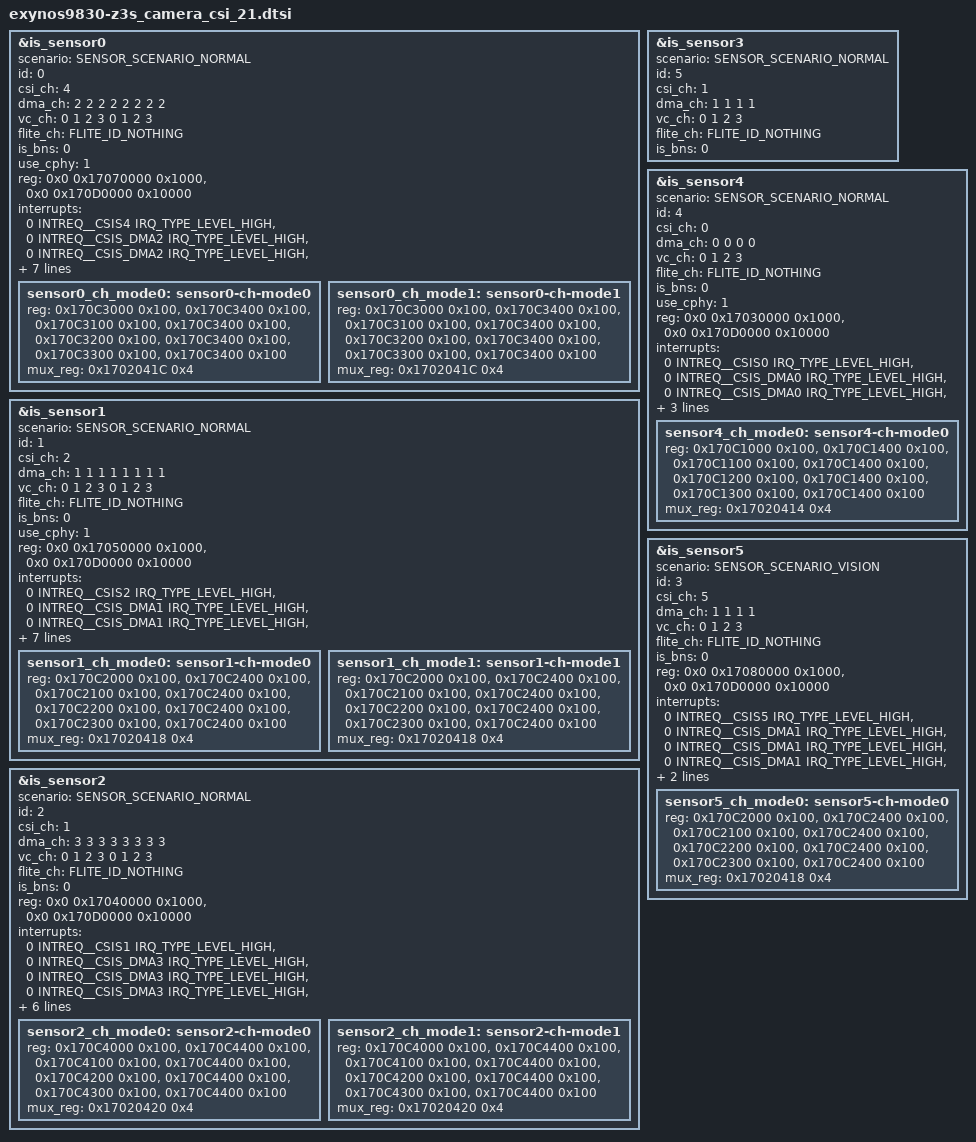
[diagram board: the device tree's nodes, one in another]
/*
 * Samsung Exynos SoC series Pablo driver
 *
 * Copyright (c) 2019 Samsung Electronics Co., Ltd
 *
 * This program is free software; you can redistribute it and/or modify
 * it under the terms of the GNU General Public License version 2 as
 * published by the Free Software Foundation.
 */

#include <dt-bindings/camera/exynos_is_dt.h>
#include <dt-bindings/interrupt-controller/exynos9830.h>
#include <dt-bindings/clock/exynos9830.h>

/* REAR CAMERA */
&is_sensor0 {
	#address-cells = <1>;
	#size-cells = <1>;
	scenario = <SENSOR_SCENARIO_NORMAL>;	/* Normal, Vision, OIS etc */
	id = <0>;
	csi_ch = <4>;
	dma_ch = <2 2 2 2
		2 2 2 2>;
	vc_ch = <0 1 2 3
		0 1 2 3>;
	flite_ch = <FLITE_ID_NOTHING>;
	is_bns = <0>;
	status = "okay";
	use_cphy = <1>;

	reg = <0x0 0x17070000 0x1000>, /* MIPI-CSI4 */
		<0x0 0x170D0000 0x10000>; /* PHY: M0S4S4S4S4S4S2 */
	reg-names = "csi", "phy";

	interrupts = <0 INTREQ__CSIS4 IRQ_TYPE_LEVEL_HIGH>, /* MIPI-CSI4 */
		<0 INTREQ__CSIS_DMA2 IRQ_TYPE_LEVEL_HIGH>,
		<0 INTREQ__CSIS_DMA2 IRQ_TYPE_LEVEL_HIGH>,
		<0 INTREQ__CSIS_DMA2 IRQ_TYPE_LEVEL_HIGH>,
		<0 INTREQ__CSIS_DMA2 IRQ_TYPE_LEVEL_HIGH>,
		<0 INTREQ__CSIS_DMA2 IRQ_TYPE_LEVEL_HIGH>,
		<0 INTREQ__CSIS_DMA2 IRQ_TYPE_LEVEL_HIGH>,
		<0 INTREQ__CSIS_DMA2 IRQ_TYPE_LEVEL_HIGH>,
		<0 INTREQ__CSIS_DMA2 IRQ_TYPE_LEVEL_HIGH>;
	interrupt-names = "csi",
		"mode0_VC0", "mode0_VC1","mode0_VC2","mode0_VC3",
		"mode1_VC0", "mode1_VC1","mode1_VC2","mode1_VC3";

	phys = <&mipi_phy_csis4_m0s4s4s4s4s4s2 0>;
	phy-names = "csis_dphy";

	/* without PAF HW */
	sensor0_ch_mode0: sensor0-ch-mode0 {
		reg = <0x170C3000 0x100>, /* DMA2 VC0 */
			<0x170C3400 0x100>, /* DMA2 Common */
			<0x170C3100 0x100>, /* DMA2 VC1 */
			<0x170C3400 0x100>, /* DMA2 Common */
			<0x170C3200 0x100>, /* DMA2 VC2 */
			<0x170C3400 0x100>, /* DMA2 Common */
			<0x170C3300 0x100>, /* DMA2 VC3 */
			<0x170C3400 0x100>; /* DMA2 Common */
		mux_reg = <0x1702041C 0x4>; /* DMA2 input mux */
	};

	/* with PAF HW */
	sensor0_ch_mode1: sensor0-ch-mode1 {
		reg = <0x170C3000 0x100>, /* DMA2 VC0 */
			<0x170C3400 0x100>, /* DMA2 Common */
			<0x170C3100 0x100>, /* DMA2 VC1 */
			<0x170C3400 0x100>, /* DMA2 Common */
			<0x170C3200 0x100>, /* DMA2 VC2 */
			<0x170C3400 0x100>, /* DMA2 Common */
			<0x170C3300 0x100>, /* DMA2 VC3 */
			<0x170C3400 0x100>; /* DMA2 Common */
		mux_reg = <0x1702041C 0x4>; /* DMA2 input mux */
	};
};

/* FRONT CAMERA */
&is_sensor1 {
	#address-cells = <1>;
	#size-cells = <1>;
	scenario = <SENSOR_SCENARIO_NORMAL>;    /* Normal, Vision, OIS etc */
	id = <1>;
	csi_ch = <2>;
	dma_ch = <1 1 1 1
		1 1 1 1>;
	vc_ch = <0 1 2 3
		0 1 2 3>;
	flite_ch = <FLITE_ID_NOTHING>;
	is_bns = <0>;
	status = "okay";
	use_cphy = <1>;

	reg = <0x0 0x17050000 0x1000>, /* MIPI-CSI2 */
	      <0x0 0x170D0000 0x10000>; /* PHY: M0S4S4S4S4S4S2 */
	reg-names = "csi", "phy";

	interrupts = <0 INTREQ__CSIS2 IRQ_TYPE_LEVEL_HIGH>, /* MIPI-CSI2 */
		<0 INTREQ__CSIS_DMA1 IRQ_TYPE_LEVEL_HIGH>,
		<0 INTREQ__CSIS_DMA1 IRQ_TYPE_LEVEL_HIGH>,
		<0 INTREQ__CSIS_DMA1 IRQ_TYPE_LEVEL_HIGH>,
		<0 INTREQ__CSIS_DMA1 IRQ_TYPE_LEVEL_HIGH>,
		<0 INTREQ__CSIS_DMA1 IRQ_TYPE_LEVEL_HIGH>,
		<0 INTREQ__CSIS_DMA1 IRQ_TYPE_LEVEL_HIGH>,
		<0 INTREQ__CSIS_DMA1 IRQ_TYPE_LEVEL_HIGH>,
		<0 INTREQ__CSIS_DMA1 IRQ_TYPE_LEVEL_HIGH>;
	interrupt-names = "csi",
		"mode0_VC0", "mode0_VC1","mode0_VC2","mode0_VC3",
		"mode1_VC0", "mode1_VC1","mode1_VC2","mode1_VC3";

	phys = <&mipi_phy_csis2_m0s4s4s4s4s4s2 0>;
	phy-names = "csis_dphy";

	/* without PAF HW */
	sensor1_ch_mode0: sensor1-ch-mode0 {
		reg = <0x170C2000 0x100>, /* DMA1 VC0 */
			<0x170C2400 0x100>, /* DMA1 Common */
			<0x170C2100 0x100>, /* DMA1 VC1 */
			<0x170C2400 0x100>, /* DMA1 Common */
			<0x170C2200 0x100>, /* DMA1 VC2 */
			<0x170C2400 0x100>, /* DMA1 Common */
			<0x170C2300 0x100>, /* DMA1 VC3 */
			<0x170C2400 0x100>; /* DMA1 Common */
		mux_reg = <0x17020418 0x4>; /* DMA1 input mux */
	};

	/* with PAF HW */
	sensor1_ch_mode1: sensor1-ch-mode1 {
		reg = <0x170C2000 0x100>, /* DMA1 VC0 */
			<0x170C2400 0x100>, /* DMA1 Common */
			<0x170C2100 0x100>, /* DMA1 VC1 */
			<0x170C2400 0x100>, /* DMA1 Common */
			<0x170C2200 0x100>, /* DMA1 VC2 */
			<0x170C2400 0x100>, /* DMA1 Common */
			<0x170C2300 0x100>, /* DMA1 VC3 */
			<0x170C2400 0x100>; /* DMA1 Common */
		mux_reg = <0x17020418 0x4>; /* DMA1 input mux */
	};
};

/* Tele CAMERA */
&is_sensor2 {
	#address-cells = <1>;
	#size-cells = <1>;
	scenario = <SENSOR_SCENARIO_NORMAL>;    /* Normal, Vision, OIS etc */
	id = <2>;
	csi_ch = <1>;
	dma_ch = <3 3 3 3
		3 3 3 3>;
	vc_ch = <0 1 2 3
		0 1 2 3>;
	flite_ch = <FLITE_ID_NOTHING>;
	is_bns = <0>;
	status = "okay";

	reg = <0x0 0x17040000 0x1000>, /* MIPI-CSI1 */
		<0x0 0x170D0000 0x10000>; /* PHY: M0S4S4S4S4S4S2 */
	reg-names = "csi", "phy";

	interrupts = <0 INTREQ__CSIS1 IRQ_TYPE_LEVEL_HIGH>, /* MIPI-CSI1 */
		<0 INTREQ__CSIS_DMA3 IRQ_TYPE_LEVEL_HIGH>,
		<0 INTREQ__CSIS_DMA3 IRQ_TYPE_LEVEL_HIGH>,
		<0 INTREQ__CSIS_DMA3 IRQ_TYPE_LEVEL_HIGH>,
		<0 INTREQ__CSIS_DMA3 IRQ_TYPE_LEVEL_HIGH>,
		<0 INTREQ__CSIS_DMA3 IRQ_TYPE_LEVEL_HIGH>,
		<0 INTREQ__CSIS_DMA3 IRQ_TYPE_LEVEL_HIGH>,
		<0 INTREQ__CSIS_DMA3 IRQ_TYPE_LEVEL_HIGH>,
		<0 INTREQ__CSIS_DMA3 IRQ_TYPE_LEVEL_HIGH>;
	interrupt-names = "csi",
		"mode0_VC0", "mode0_VC1","mode0_VC2","mode0_VC3",
		"mode1_VC0", "mode1_VC1","mode1_VC2","mode1_VC3";

	phys = <&mipi_phy_csis1_m0s4s4s4s4s4s2 0>;
	phy-names = "csis_dphy";

	/* without PAF HW */
	sensor2_ch_mode0: sensor2-ch-mode0 {
		reg = <0x170C4000 0x100>, /* DMA3 VC0 */
			<0x170C4400 0x100>, /* DMA3 Common */
			<0x170C4100 0x100>, /* DMA3 VC1 */
			<0x170C4400 0x100>, /* DMA3 Common */
			<0x170C4200 0x100>, /* DMA3 VC2 */
			<0x170C4400 0x100>, /* DMA3 Common */
			<0x170C4300 0x100>, /* DMA3 VC3 */
			<0x170C4400 0x100>; /* DMA3 Common */
		mux_reg = <0x17020420 0x4>; /* DMA3 input mux */
	};

	/* with PAF HW */
	sensor2_ch_mode1: sensor2-ch-mode1 {
		reg = <0x170C4000 0x100>, /* DMA3 VC0 */
			<0x170C4400 0x100>, /* DMA3 Common */
			<0x170C4100 0x100>, /* DMA3 VC1 */
			<0x170C4400 0x100>, /* DMA3 Common */
			<0x170C4200 0x100>, /* DMA3 VC2 */
			<0x170C4400 0x100>, /* DMA3 Common */
			<0x170C4300 0x100>, /* DMA3 VC3 */
			<0x170C4400 0x100>; /* DMA3 Common */
		mux_reg = <0x17020420 0x4>; /* DMA3 input mux */
	};
};

/* Reseved: FRONT SUB */
&is_sensor3 {
	#address-cells = <1>;
	#size-cells = <1>;
	scenario = <SENSOR_SCENARIO_NORMAL>;    /* Normal, Vision, OIS etc */
	id = <5>;
	csi_ch = <1>;
	dma_ch = <1 1 1 1>;
	vc_ch = <0 1 2 3>;
	flite_ch = <FLITE_ID_NOTHING>;
	is_bns = <0>;
	status = "okay";
};

/* ULTRA WIDE CAMERA */
&is_sensor4 {
	#address-cells = <1>;
	#size-cells = <1>;
	scenario = <SENSOR_SCENARIO_NORMAL>;    /* Normal, Vision, OIS etc */
	id = <4>;
	csi_ch = <0>;
	dma_ch = <0 0 0 0>;
	vc_ch = <0 1 2 3>;
	flite_ch = <FLITE_ID_NOTHING>;
	is_bns = <0>;
	status = "okay";
	use_cphy = <1>;

	reg = <0x0 0x17030000 0x1000>, /* MIPI-CSI0 */
		<0x0 0x170D0000 0x10000>; /* PHY: M0S4S4S4S4S4S2 */
	reg-names = "csi", "phy";

	interrupts = <0 INTREQ__CSIS0 IRQ_TYPE_LEVEL_HIGH>, /*MIPI-CSI0 */
		<0 INTREQ__CSIS_DMA0 IRQ_TYPE_LEVEL_HIGH>,
		<0 INTREQ__CSIS_DMA0 IRQ_TYPE_LEVEL_HIGH>,
		<0 INTREQ__CSIS_DMA0 IRQ_TYPE_LEVEL_HIGH>,
		<0 INTREQ__CSIS_DMA0 IRQ_TYPE_LEVEL_HIGH>;
	interrupt-names = "csi",
			"mode0_VC0", "mode0_VC1","mode0_VC2","mode0_VC3";

	phys = <&mipi_phy_csis0_m0s4s4s4s4s4s2 0>;
	phy-names = "csis_dphy";

	/* without PAF HW */
	sensor4_ch_mode0: sensor4-ch-mode0 {
		reg = <0x170C1000 0x100>, /* DMA0 VC0 */
			<0x170C1400 0x100>, /* DMA0 Common */
			<0x170C1100 0x100>, /* DMA0 VC1 */
			<0x170C1400 0x100>, /* DMA0 Common */
			<0x170C1200 0x100>, /* DMA0 VC2 */
			<0x170C1400 0x100>, /* DMA0 Common */
			<0x170C1300 0x100>, /* DMA0 VC3 */
			<0x170C1400 0x100>; /* DMA0 Common */
		mux_reg = <0x17020414 0x4>; /* DMA0 input mux */
	};
};

/* REAR TOF */
&is_sensor5 {
	#address-cells = <1>;
	#size-cells = <1>;
	scenario = <SENSOR_SCENARIO_VISION>;    /* Normal, Vision, OIS etc */
	id =  <3>;
	csi_ch = <5>;
	dma_ch = <1 1 1 1>;
	vc_ch = <0 1 2 3>;
	flite_ch = <FLITE_ID_NOTHING>;
	is_bns = <0>;
	status = "okay";

	reg = <0x0 0x17080000 0x1000>, /* MIPI-CSI5 */
		<0x0 0x170D0000 0x10000>; /* PHY: M0S4S4S4S4S4S2 */
	reg-names = "csi", "phy";

	interrupts = <0 INTREQ__CSIS5 IRQ_TYPE_LEVEL_HIGH>, /* MIPI-CSI5 */
			<0 INTREQ__CSIS_DMA1 IRQ_TYPE_LEVEL_HIGH>,
			<0 INTREQ__CSIS_DMA1 IRQ_TYPE_LEVEL_HIGH>,
			<0 INTREQ__CSIS_DMA1 IRQ_TYPE_LEVEL_HIGH>,
			<0 INTREQ__CSIS_DMA1 IRQ_TYPE_LEVEL_HIGH>;

	phys = <&mipi_phy_csis5_m0s4s4s4s4s4s2 0>;
	phy-names = "csis_dphy";

	/* without PAF HW */
	sensor5_ch_mode0: sensor5-ch-mode0 {
		reg = <0x170C2000 0x100>, /* DMA1 VC0 */
			<0x170C2400 0x100>, /* DMA1 Common */
			<0x170C2100 0x100>, /* DMA1 VC1 */
			<0x170C2400 0x100>, /* DMA1 Common */
			<0x170C2200 0x100>, /* DMA1 VC2 */
			<0x170C2400 0x100>, /* DMA1 Common */
			<0x170C2300 0x100>, /* DMA1 VC3 */
			<0x170C2400 0x100>; /* DMA1 Common */
		mux_reg = <0x17020418 0x4>; /* DMA1 input mux */
	};
};
